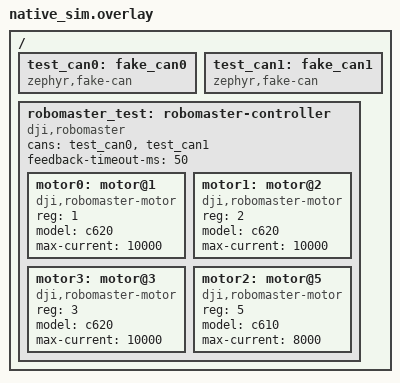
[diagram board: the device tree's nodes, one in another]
/ {
	test_can0: fake_can0 {
		compatible = "zephyr,fake-can";
		status = "okay";
	};

	test_can1: fake_can1 {
		compatible = "zephyr,fake-can";
		status = "okay";
	};

	robomaster_test: robomaster-controller {
		compatible = "dji,robomaster";
		#address-cells = <1>;
		#size-cells = <0>;
		cans = <&test_can0 &test_can1>;
		feedback-timeout-ms = <50>;

		motor0: motor@1 {
			compatible = "dji,robomaster-motor";
			reg = <1>;
			model = "c620";
			max-current = <10000>;
		};

		motor1: motor@2 {
			compatible = "dji,robomaster-motor";
			reg = <2>;
			model = "c620";
			max-current = <10000>;
		};

		motor3: motor@3 {
			compatible = "dji,robomaster-motor";
			reg = <3>;
			model = "c620";
			max-current = <10000>;
		};

		motor2: motor@5 {
			compatible = "dji,robomaster-motor";
			reg = <5>;
			model = "c610";
			max-current = <8000>;
		};
	};
};
